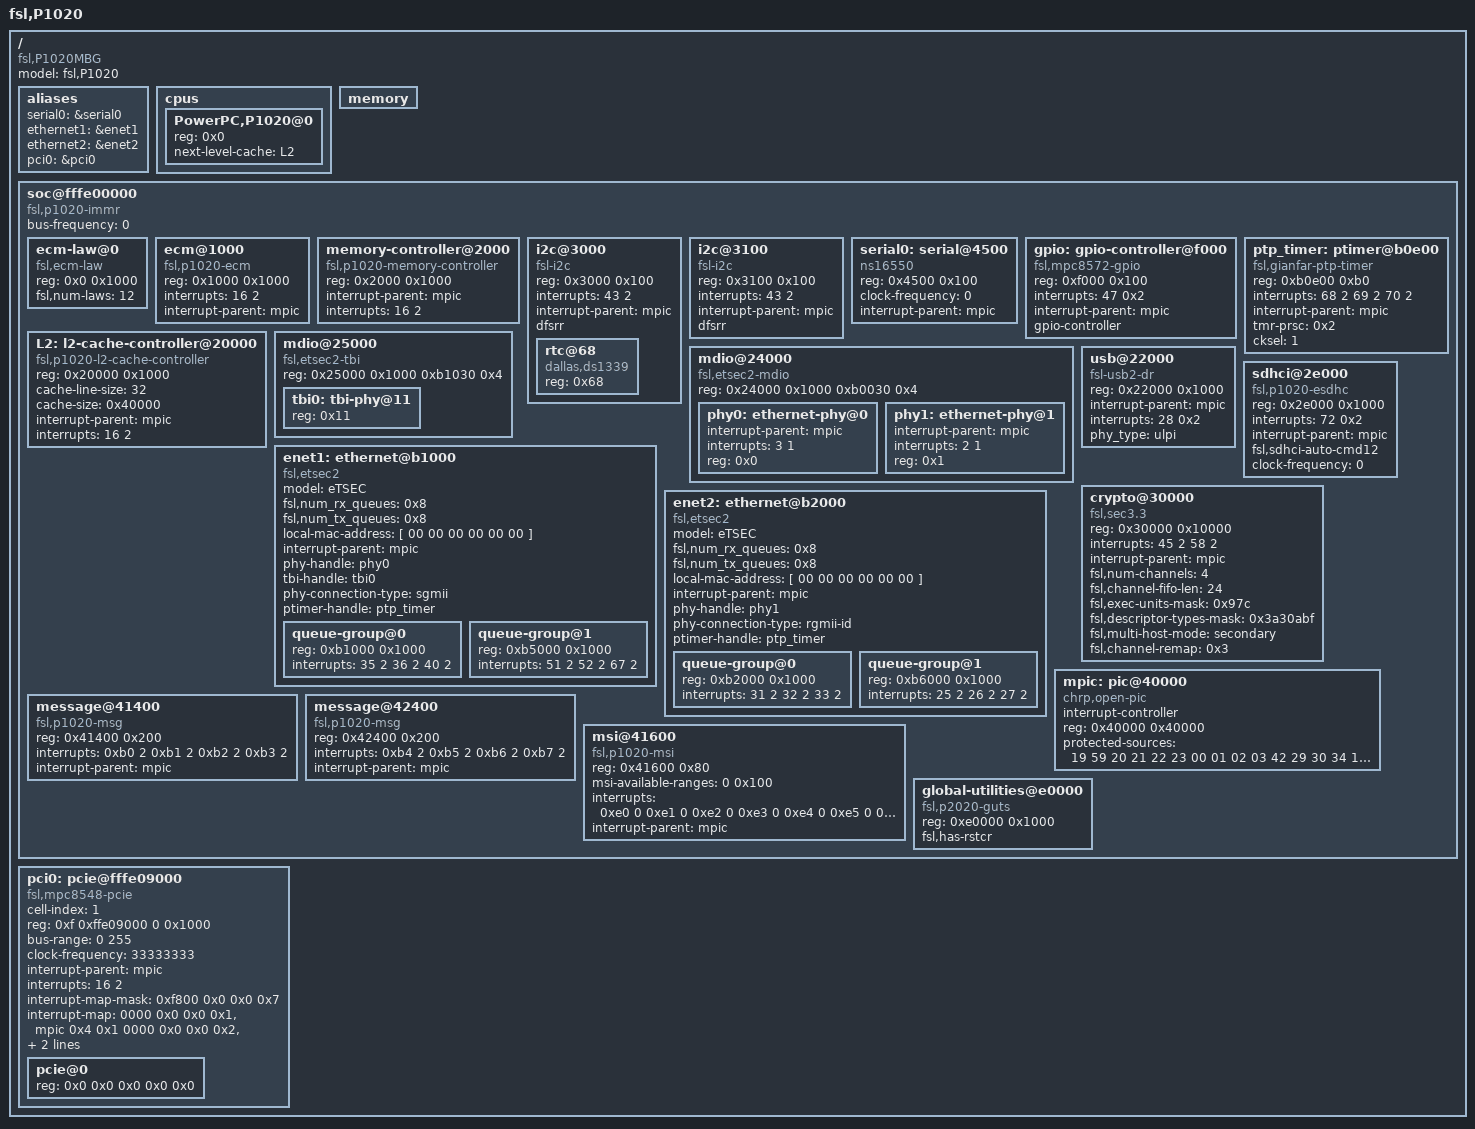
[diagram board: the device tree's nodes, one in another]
/*
 * P1020 MBG Core0 36bit Device Tree Source in CAMP mode.
 *
 * In CAMP mode, each core needs to have its own dts. Only mpic and L2 cache
 * can be shared, all the other devices must be assigned to on core only.
 * This dts file allows core0 to have ecm, memory, i2c, gpio, serial0,
 * usb, mdio, eth1, eth2, sdhc, crypto, global-util, message, pci0, msi.
 *
 * Please note to add "-b 0" for core0's dts compiling.
 *
 * Copyright 2011 Freescale Semiconductor Inc.
 *
 * This program is free software; you can redistribute  it and/or modify it
 * under  the terms of  the GNU General  Public License as published by the
 * Free Software Foundation;  either version 2 of the  License, or (at your
 * option) any later version.
 */

/dts-v1/;
/ {
	model = "fsl,P1020";
	compatible = "fsl,P1020MBG";
	#address-cells = <2>;
	#size-cells = <2>;

	aliases {
		serial0 = &serial0;
		ethernet1 = &enet1;
		ethernet2 = &enet2;
		pci0 = &pci0;
	};

	cpus {
		#address-cells = <1>;
		#size-cells = <0>;

		PowerPC,P1020@0 {
			device_type = "cpu";
			reg = <0x0>;
			next-level-cache = <&L2>;
		};
	};

	memory {
		device_type = "memory";
	};

	soc@fffe00000 {
		#address-cells = <1>;
		#size-cells = <1>;
		device_type = "soc";
		compatible = "fsl,p1020-immr", "simple-bus";
		ranges = <0x0  0xf 0xffe00000 0x100000>;
		bus-frequency = <0>;		// Filled out by uboot.

		ecm-law@0 {
			compatible = "fsl,ecm-law";
			reg = <0x0 0x1000>;
			fsl,num-laws = <12>;
		};

		ecm@1000 {
			compatible = "fsl,p1020-ecm", "fsl,ecm";
			reg = <0x1000 0x1000>;
			interrupts = <16 2>;
			interrupt-parent = <&mpic>;
		};

		memory-controller@2000 {
			compatible = "fsl,p1020-memory-controller";
			reg = <0x2000 0x1000>;
			interrupt-parent = <&mpic>;
			interrupts = <16 2>;
		};

		i2c@3000 {
			#address-cells = <1>;
			#size-cells = <0>;
			compatible = "fsl-i2c";
			reg = <0x3000 0x100>;
			interrupts = <43 2>;
			interrupt-parent = <&mpic>;
			dfsrr;
			rtc@68 {
				compatible = "dallas,ds1339";
				reg = <0x68>;
			};
		};

		i2c@3100 {
			#address-cells = <1>;
			#size-cells = <0>;
			compatible = "fsl-i2c";
			reg = <0x3100 0x100>;
			interrupts = <43 2>;
			interrupt-parent = <&mpic>;
			dfsrr;
		};

		serial0: serial@4500 {
			device_type = "serial";
			compatible = "ns16550";
			reg = <0x4500 0x100>;
			clock-frequency = <0>;
			interrupt-parent = <&mpic>;
		};

		gpio: gpio-controller@f000 {
			#gpio-cells = <2>;
			compatible = "fsl,mpc8572-gpio";
			reg = <0xf000 0x100>;
			interrupts = <47 0x2>;
			interrupt-parent = <&mpic>;
			gpio-controller;
		};

		L2: l2-cache-controller@20000 {
			compatible = "fsl,p1020-l2-cache-controller";
			reg = <0x20000 0x1000>;
			cache-line-size = <32>;	// 32 bytes
			cache-size = <0x40000>; // L2,256K
			interrupt-parent = <&mpic>;
			interrupts = <16 2>;
		};

		mdio@24000 {
			#address-cells = <1>;
			#size-cells = <0>;
			compatible = "fsl,etsec2-mdio";
			reg = <0x24000 0x1000 0xb0030 0x4>;

			phy0: ethernet-phy@0 {
				interrupt-parent = <&mpic>;
				interrupts = <3 1>;
				reg = <0x0>;
			};
			phy1: ethernet-phy@1 {
				interrupt-parent = <&mpic>;
				interrupts = <2 1>;
				reg = <0x1>;
			};
		};

		mdio@25000 {
			#address-cells = <1>;
			#size-cells = <0>;
			compatible = "fsl,etsec2-tbi";
			reg = <0x25000 0x1000 0xb1030 0x4>;

			tbi0: tbi-phy@11 {
				reg = <0x11>;
				device_type = "tbi-phy";
			};
		};

		ptp_timer: ptimer@b0e00 {
			compatible = "fsl,gianfar-ptp-timer";
			reg = <0xb0e00 0xb0>;
			interrupts = <68 2 69 2 70 2>;
			interrupt-parent = <&mpic>;
			tmr-prsc = <0x2>;
			cksel = <1>;
		};

		enet1: ethernet@b1000 {
			#address-cells = <1>;
			#size-cells = <1>;
			device_type = "network";
			model = "eTSEC";
			compatible = "fsl,etsec2";
			fsl,num_rx_queues = <0x8>;
			fsl,num_tx_queues = <0x8>;
			local-mac-address = [ 00 00 00 00 00 00 ];
			interrupt-parent = <&mpic>;
			phy-handle = <&phy0>;
			tbi-handle = <&tbi0>;
			phy-connection-type = "sgmii";
			ptimer-handle = <&ptp_timer>;

			queue-group@0 {
				#address-cells = <1>;
				#size-cells = <1>;
				reg = <0xb1000 0x1000>;
				interrupts = <35 2 36 2 40 2>;
			};
			queue-group@1 {
				#address-cells = <1>;
				#size-cells = <1>;
				reg = <0xb5000 0x1000>;
				interrupts = <51 2 52 2 67 2>;
			};
		};

		enet2: ethernet@b2000 {
			#address-cells = <1>;
			#size-cells = <1>;
			device_type = "network";
			model = "eTSEC";
			compatible = "fsl,etsec2";
			fsl,num_rx_queues = <0x8>;
			fsl,num_tx_queues = <0x8>;
			local-mac-address = [ 00 00 00 00 00 00 ];
			interrupt-parent = <&mpic>;
			phy-handle = <&phy1>;
			phy-connection-type = "rgmii-id";
			ptimer-handle = <&ptp_timer>;

			queue-group@0 {
				#address-cells = <1>;
				#size-cells = <1>;
				reg = <0xb2000 0x1000>;
				interrupts = <31 2 32 2 33 2>;
			};

			queue-group@1 {
				#address-cells = <1>;
				#size-cells = <1>;
				reg = <0xb6000 0x1000>;
				interrupts = <25 2 26 2 27 2>;
			};
		};

		usb@22000 {
			#address-cells = <1>;
			#size-cells = <0>;
			compatible = "fsl-usb2-dr";
			reg = <0x22000 0x1000>;
			interrupt-parent = <&mpic>;
			interrupts = <28 0x2>;
			phy_type = "ulpi";
		};

		/* USB2 is shared with localbus, so it must be disabled
		   by default. We can't put 'status = "disabled";' here
		   since U-Boot doesn't clear the status property when
		   it enables USB2. OTOH, U-Boot does create a new node
		   when there isn't any. So, just comment it out.
		usb@23000 {
			#address-cells = <1>;
			#size-cells = <0>;
			compatible = "fsl-usb2-dr";
			reg = <0x23000 0x1000>;
			interrupt-parent = <&mpic>;
			interrupts = <46 0x2>;
			phy_type = "ulpi";
		};
		*/

		sdhci@2e000 {
			compatible = "fsl,p1020-esdhc", "fsl,esdhc";
			reg = <0x2e000 0x1000>;
			interrupts = <72 0x2>;
			interrupt-parent = <&mpic>;
			fsl,sdhci-auto-cmd12;
			/* Filled in by U-Boot */
			clock-frequency = <0>;
		};

		crypto@30000 {
			compatible = "fsl,sec3.3", "fsl,sec3.1",
				     "fsl,sec3.0", "fsl,sec2.4",
				     "fsl,sec2.2", "fsl,sec2.1", "fsl,sec2.0";
			reg = <0x30000 0x10000>;
			interrupts = <45 2 58 2>;
			interrupt-parent = <&mpic>;
			fsl,num-channels = <4>;
			fsl,channel-fifo-len = <24>;
			fsl,exec-units-mask = <0x97c>;
			fsl,descriptor-types-mask = <0x3a30abf>;
			fsl,multi-host-mode = "secondary";
			fsl,channel-remap = <0x3>;
		};

		mpic: pic@40000 {
			interrupt-controller;
			#address-cells = <0>;
			#interrupt-cells = <2>;
			reg = <0x40000 0x40000>;
			compatible = "chrp,open-pic";
			device_type = "open-pic";
			protected-sources = <
			19 59			/* localbus spi */
			20 21 22 23		/* dma */
			00 01 02 03		/* pci1 */
			42 29 30 34		/* serial0, enet0-queue-group0 */
			17 18 24 45		/* enet0-queue-group1, crypto */
			>;
		};

		message@41400 {
			compatible = "fsl,p1020-msg", "fsl,mpic-msg";
			reg = <0x41400 0x200>;
			interrupts = <
				0xb0 2
				0xb1 2
				0xb2 2
				0xb3 2>;
			interrupt-parent = <&mpic>;
		};

		message@42400 {
			compatible = "fsl,p1020-msg", "fsl,mpic-msg";
			reg = <0x42400 0x200>;
			interrupts = <
				0xb4 2
				0xb5 2
				0xb6 2
				0xb7 2>;
			interrupt-parent = <&mpic>;
		};

		msi@41600 {
			compatible = "fsl,p1020-msi", "fsl,mpic-msi";
			reg = <0x41600 0x80>;
			msi-available-ranges = <0 0x100>;
			interrupts = <
				0xe0 0
				0xe1 0
				0xe2 0
				0xe3 0
				0xe4 0
				0xe5 0
				0xe6 0
				0xe7 0>;
			interrupt-parent = <&mpic>;
		};

		global-utilities@e0000 {
			compatible = "fsl,p2020-guts";
			reg = <0xe0000 0x1000>;
			fsl,has-rstcr;
		};
	};

	pci0: pcie@fffe09000 {
		cell-index = <1>;
		compatible = "fsl,mpc8548-pcie";
		device_type = "pci";
		#interrupt-cells = <1>;
		#size-cells = <2>;
		#address-cells = <3>;
		reg = <0xf 0xffe09000 0 0x1000>;
		bus-range = <0 255>;
		ranges = <0x2000000 0x0 0xc0000000 0xc 0x20000000 0x0 0x20000000
			  0x1000000 0x0 0x00000000 0xf 0xffc10000 0x0 0x10000>;
		clock-frequency = <33333333>;
		interrupt-parent = <&mpic>;
		interrupts = <16 2>;
		interrupt-map-mask = <0xf800 0x0 0x0 0x7>;
		interrupt-map = <
			/* IDSEL 0x0 */
			0000 0x0 0x0 0x1 &mpic 0x4 0x1
			0000 0x0 0x0 0x2 &mpic 0x5 0x1
			0000 0x0 0x0 0x3 &mpic 0x6 0x1
			0000 0x0 0x0 0x4 &mpic 0x7 0x1
			>;
		pcie@0 {
			reg = <0x0 0x0 0x0 0x0 0x0>;
			#size-cells = <2>;
			#address-cells = <3>;
			device_type = "pci";
			ranges = <0x2000000 0x0 0xc0000000
				  0x2000000 0x0 0xc0000000
				  0x0 0x20000000

				  0x1000000 0x0 0x0
				  0x1000000 0x0 0x0
				  0x0 0x100000>;
		};
	};
};
